# NANO112AN_v1 register map
File version: 1.0
Registers are 32-bit, read-write, reset 0x0 unless marked. A register's access mark holds for its fields unless they carry their own. Offsets are from the block's base; [hi:lo] are bit positions; {n}, {i} and the like mark numbered series; 'fields as' and 'values as' point back to an identical list.

## TMR0 — TMR Register Map
Base 0x40010000
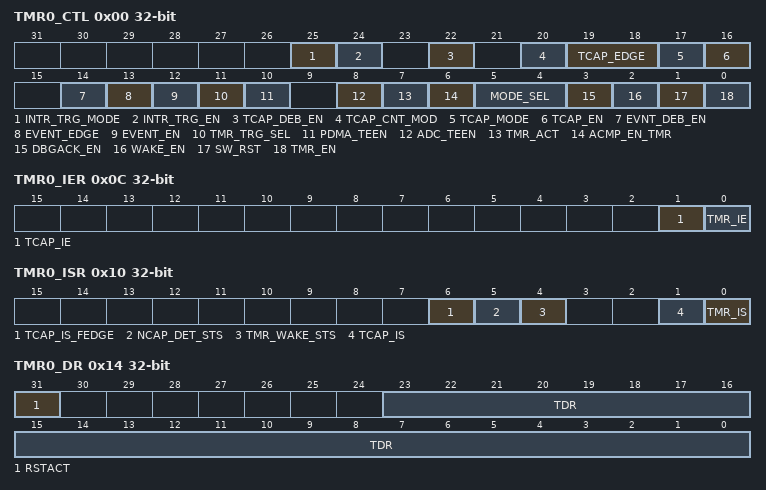
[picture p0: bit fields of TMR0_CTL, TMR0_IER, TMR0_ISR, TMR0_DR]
0x00 TMR0_CTL — Timer 0 Control Register
  [25] INTR_TRG_MODE — Inter-timer Trigger Mode Selection. This bit controls the timer operation mode when inter-timer trigger function is enabled. When this bit is low, the TMRx will be in counter mode and counting with external Clock Source or event. In addition, TMRx+1 will be in trigger-counting mode of capture function. In this mode, TMRx_CMPR control when inter-timer trigger function terminated. When this bit is high, the TMRx will be in counter mode and counting with external Clock Source or event. In addition, TMRx+1 will be in trigger-counting mode of capture function. In this mode, TMRx+1_CMPR control when inter-timer trigger function terminated. In this mode, TMRx would ignore some incoming event based on the EVNT_DROP_CNT (TMRx_ECTL[31:24]). And once the TMRx+1 counter value equal or large than TMRx+1_CMPR, TMRx would terminate the operation when next incoming event received. Note: For TMRx+1_CTL, this bit is ignored and the read back value is always 0.
    0=Inter-Timer Trigger function wouldn't ignore any incoming event; 1=Inter-Timer Trigger function would ignore incoming event based on the EVNT_DROP_CNT (TMRx_ECTL[31:24])
  [24] INTR_TRG_EN — Inter-timer Trigger Function Enable Control. This bit controls if Inter-timer Trigger function is enabled. If Inter-timer Trigger function is enabled, the TMRx will be in counter mode and counting with external Clock Source or event. In addition, TMRx+1 will be in trigger-counting mode of capture function. Note: For TMRx+1_CTL, this bit is ignored and the read back value is always 0.
    0=Inter-timer trigger function Disabled; 1=Inter-timer trigger function Enabled
  [22] TCAP_DEB_EN — TC Pin De-bounce Enable Control. When CAP_DEB_EN (TMRx_CTL[22]) is set, the TC pin de-bounce circuit will be enabled to eliminate the bouncing of the signal. In de-bounce circuit the TC pin signal will be sampled 4 times by TMRx_CLK. Note: When TCAP_EN (TMRx_CTL[16]) is enabled, enable this bit is recommended. And, while TCAP_EN (TMRx_CTL[16]) is disabled, disable this bit is recommended to save power consumption. Note: When CAP_SRC (TMRx_ECTL[16]) is high, the capture signal is from internal of chip and the de-bounce circuit would not take effect no matter this bit is high or low. Note: For Timer 1 and 3, when INTR_TRG_EN (TMRx_CTL[24]) is high, the capture signal is from internal of chip and the de-bounce circuit would not take effect no matter this bit is high or low.
    0=De-bounce circuit Disabled; 1=De-bounce circuit Enabled
  [20] TCAP_CNT_MOD — Timer Capture Counting Mode Selection. This bit indicates the behavior of 24-bit up-counting timer while TCAP_EN (TMRx_CTL[16]) is set to high. If this bit is 0, the free-counting mode, the behavior of 24-bit up-counting timer is defined by MODE_SEL (TMRx_CTL[5:4]) field. When TCAP_EN (TMRx_CTL[16]) is set, TCAP_MODE (TMRx_CTL[17]) is 0, and the transition of TC pin matches the TCAP_EDGE (TMRx_CTL[19:18]) setting, the value of 24-bit up-counting timer will be saved into register TMRx_TCAP. If this bit is 1, Trigger-counting mode, 24-bit up-counting timer will be not counting and keep its value at 0. When TCAP_EN (TMRx_CTL[16]) is set, TCAP_MODE (TMRx_CTL[17]) is 0, and once the transition of external pin matches the 1st transition of TCAP_EDGE (TMRx_CTL[19:18]) setting, the 24-bit up-counting timer will start counting. And then if the transition of external pin matches the 2nd transition of TCAP_EDGE (TMRx_CTL[19:18]) setting, the 24-bit up-counting timer will stop counting. And its value will be saved into register TMRx_TCAP.
    0=Capture with free-counting timer mode; 1=Capture with trigger-counting timer mode
  [19:18] TCAP_EDGE — TC Pin Edge Detect Selection
  [17] TCAP_MODE — TC Pin Function Mode Selection. This bit indicates if the transition on TC pin is used as timer counter reset function or timer capture function.
    0=The transition on TC pin is used as timer capture function; 1=The transition on TC pin is used as timer counter reset function
  [16] TCAP_EN — TC Pin Functional Enable Control. This bit controls if the transition on TC pin could be used as timer counter reset function or timer capture function.
    0=The transition on TC pin is ignored; 1=The transition on TC pin will result in the capture or reset of 24-bit timer counter
  [14] EVNT_DEB_EN — External Event De-bounce Enable Control. When EVNT_DEB_EN is set, the external event pin de-bounce circuit will be enabled to eliminate the bouncing of the signal. In de-bounce circuit the external event pin will be sampled 4 times by TMRx_CLK. Note: When EVENT_EN (TMRx_CTL[12]) is enabled, enable this bit is recommended. And, while EVENT_EN (TMRx_CTL[12]) is disabled, disable this bit is recommended to save power consumption.
    0=De-bounce circuit Disabled; 1=De-bounce circuit Enabled
  [13] EVENT_EDGE — Event Counting Mode Edge Selection. This bit indicates which edge of external event pin enabling the timer to increase 1.
    0=A falling edge of external event enabling the timer to increase 1; 1=A rising edge of external event enabling the timer to increase 1
  [12] EVENT_EN — Event Counting Mode Enable Control. When EVENT_EN is set, the increase of 24-bit up-counting timer is controlled by external event pin. While the transition of external event pin matches the definition of EVENT_EDGE (TMRx_CTL[13]), the 24-bit up-counting timer increases by 1. Or, the 24-bit up-counting timer will keep its value unchanged.
    0=Timer counting is not controlled by external event pin; 1=Timer counting is controlled by external event pin
  [11] TMR_TRG_SEL — Timer Trigger Selection. This bit controls if the TMR_IS (TMRx_ISR[0]) or TCAP_IS (TMRx_ISR[1]) is used to trigger PDMA and ADC while TMR_IS (TMRx_ISR[0]) or TCAP_IS (TMRx_ISR[1]) is set. If this bit is low and TMR_IS (TMRx_ISR[0]) is set, timer will generate an internal trigger event to PDMA or ADC while related trigger enable bit (PDMA_TEEN (TMRx_CTL[10]) or ADC_TEEN (TMRx_CTL[8])) is set. If this bit is set high and TCAP_IS (TMRx_ISR[0]) is set, timer will generate an internal trigger event to PDMA or ADC while related trigger enable bit (PDMA_TEEN (TMRx_CTL[10]) or ADC_TEEN (TMRx_CTL[8])) is set.
    0=TMR_IS (TMRx_ISR[0]) is used to trigger PDMA and ADC; 1=TCAP_IS (TMRx_ISR[1]) is used to trigger PDMA and ADC
  [10] PDMA_TEEN — Timer Trigger PDMA Enable Control. This bit controls if TMR_IS (TMRx_ISR[0]) or TCAP_IS (TMRx_ISR[1]) could trigger PDMA. When PDMA_TEEN is set, TMR_IS (TMRx_ISR[0]) is set and the CAP_TRG_EN (TMRx_CTL[11]) is low, the timer controller will generate an internal trigger event to PDMA controller. When PDMA_TEEN is set, TCAP_IS (TMRx_ISR[1]) is set and the CAP_TRG_EN (TMRx_CTL[11]) is high, the timer controller will generate an internal trigger event to PDMA controller.
    0=TMR_IS (TMRx_ISR[0]) or TCAP_IS (TMRx_ISR[1]) trigger PDMA Disabled; 1=TMR_IS (TMRx_ISR[0]) or TCAP_IS (TMRx_ISR[1]) trigger PDMA Enabled
  [8] ADC_TEEN — Timer Trigger ADC Enable Control. This bit controls if TMR_IS (TMRx_ISR[0]) or TCAP_IS (TMRx_ISR[1]) could trigger ADC. When ADC_TEEN is set, TMR_IS (TMRx_ISR[0]) is set and the CAP_TRG_EN (TMRx_CTL[11]) is low, the timer controller will generate an internal trigger event to ADC controller. When ADC_TEEN is set, TCAP_IS (TMRx_ISR[1]) is set and the CAP_TRG_EN (TMRx_CTL[11]) is high, the timer controller will generate an internal trigger event to ADC controller.
    0=TMR_IS (TMRx_ISR[0]) or TCAP_IS (TMRx_ISR[1]) trigger ADC Disabled; 1=TMR_IS (TMRx_ISR[0]) or TCAP_IS (TMRx_ISR[1]) trigger ADC Enabled
  [7] TMR_ACT ro — Timer Active Status Bit (Read Only). This bit indicates the timer counter status of timer.
    0=Timer is not active; 1=Timer is in active
  [6] ACMP_EN_TMR — ACMP Trigger Timer Enable Control. This bit high enables the functionality that when ACMP0 is in sigma-delta mode, it could enable Timer.
    0=ACMP0 trigger timer functionality disabled; 1=ACMP0 trigger timer functionality enabled
  [5:4] MODE_SEL — Timer Operating Mode Select
  [3] DBGACK_EN — ICE Debug Mode Acknowledge Ineffective Enable Control
    0=ICE debug mode acknowledgement effects TIMER counting and TIMER counter will be held while ICE debug mode acknowledged; 1=ICE debug mode acknowledgement is ineffective and TIMER counter will keep going no matter ICE debug mode acknowledged or not
  [2] WAKE_EN — Wake-up Enable Control. When WAKE_EN is set and the TMR_IS (TMRx_ISR[0]) or TCAP_IS (TMRx_ISR[1]) is set, the timer controller will generate a wake-up trigger event to CPU.
    0=Wake-up trigger event Disabled; 1=Wake-up trigger event Enabled
  [1] SW_RST — Software Reset. Set this bit will reset the timer counter, pre-scale counter and also force TMR_EN (TMRx_CTL [0]) to 0. Note: This bit will be auto cleared and takes at least 3 TMRx_CLK clock cycles.
    0=No effect; 1=Reset Timer's pre-scale counter, internal 24-bit up-counter and TMR_EN (TMRx_CTL [0]) bit
  [0] TMR_EN — Timer Counter Enable Control
    0=Stops/Suspends counting; 1=Starts counting
0x04 TMR0_PRECNT — Timer 0 Pre-scale Counter Register
  [7:0] PRESCALE_CNT — Pre-scale Counter
0x08 TMR0_CMPR — Timer 0 Compare Register
  [23:0] TMR_CMP — Timer Compared Value. TMR_CMP is a 24-bit compared register. When the internal 24-bit up-counter counts and its value is equal to TMR_CMP value, a Timer Interrupt is requested if the timer interrupt is enabled with TMR_EN (TMRx_CTL [0]) is enabled. The TMR_CMP value defines the timer counting cycle time. Note1: Never write 0x0 or 0x1 in TMR_CMP, or the core will run into unknown state. Note2: No matter TMR_EN (TMRx_CTL [0]) is 0 or 1, whenever software write a new value into this register, TIMER will restart counting using this new value and abort previous count.
0x0C TMR0_IER — Timer 0 Interrupt Enable Register
  [1] TCAP_IE — Timer Capture Function Interrupt Enable Control. Note: If timer external pin function interrupt is enabled, the timer asserts its interrupt signal when the TCAP_EN (TMRx_CTL[16]) is set and the transition of external pin matches the TCAP_EDGE (TMRx_CTL[19:18]) setting
    0=Timer External Pin Function Interrupt Disabled; 1=Timer External Pin Function Interrupt Enabled
  [0] TMR_IE — Timer Interrupt Enable Control. Note: If timer interrupt is enabled, the timer asserts its interrupt signal when the associated counter is equal to TMR_CMPR.
    0=Timer Interrupt Disabled; 1=Timer Interrupt Enabled
0x10 TMR0_ISR — Timer 0 Interrupt Status Register
  [6] TCAP_IS_FEDGE — TC Pin Edge Detect Is Falling. This flag indicates the edge detected in TC pin is rising edge or falling edge. Timer only updates this flag when it udpates the Timer Capture Data (TMR_TCAP[23:0]) value. When a new incoming capture event detected before CPU clearing the TCAP_IS (TMRx_ISR[1]) status, Timer will keep this bit unchanged.
    0=TC pin edge detected is rising edge; 1=TC pin edge detected is falling edge
  [5] NCAP_DET_STS — New Capture Detected Status. This status is to indicate there is a new incoming capture event detected before CPU clearing the TCAP_IS (TMRx_ISR[1]) status. If the above condition occurred, the Timer will keep register TMRx_TCAP unchanged and drop the new capture value. Write 1 to clear this bit to 0.
    0=New incoming capture event didn't detect before CPU clearing TCAP_IS (TMRx_ISR[1]) status; 1=New incoming capture event detected before CPU clearing TCAP_IS (TMRx_ISR[1]) status
  [4] TMR_WAKE_STS — Timer Wake-up Status. If timer causes CPU wakes up from Power-down mode, this bit will be set to high. It must be cleared by software with a write 1 to this bit.
    0=Timer does not cause system wake-up; 1=Wakes system up from Power-down mode by Timer timeout
  [1] TCAP_IS — Timer Capture Function Interrupt Status. This bit indicates the external pin function interrupt status of Timer. This bit is set by hardware when TCAP_EN (TMRx_CTL[16]) is set high, and the transition of external pin matches the TCAP_EDGE (TMRx_CTL[19:18]) setting. Write 1 to clear this bit to 0. If this bit is active and TCAP_IE (TMRx_IER[1]) is enabled, Timer will trigger an interrupt to CPU.
  [0] TMR_IS — Timer Interrupt Status. This bit indicates the interrupt status of Timer. This bit is set by hardware when the up counting value of internal 24-bit counter matches the timer compared value (TMR_CMPR). Write 1 to clear this bit to 0. If this bit is active and TMR_IE (TMRx_IER[0]) is enabled, Timer will trigger an interrupt to CPU.
0x14 TMR0_DR — Timer 0 Data Register
  [31] RSTACT — Reset Active. This bit indicates if the counter reset operation active. When user write this register, timer starts to reset its internal 24-bit timer up-counter and 8-bit pre-scale counter to 0. In the same time, timer set this flag to 1 to indicate the counter reset operation is in progress. Once the counter reset operation done, timer clear this bit to 0 automatically. Note: This bit is read only. Write operation wouldn't take any effect.
    0=Reset operation done; 1=Reset operation triggered by writing TMR_DR is in progress
  [23:0] TDR — Timer Data Register (Read). User can read this register for internal 24-bit timer up-counter value. Counter Reset (Write). User can write any value to this register to reset internal 24-bit timer up-counter and 8-bit pre-scale counter. This reset operation wouldn't affect any other timer control registers and circuit. After reset completed, the 24-bit timer up-counter and 8-bit pre-scale counter restart the counting based on the TMRx_CTL register setting.
0x18 TMR0_TCAP ro — Timer 0 Capture Data Register
  [23:0] CAP — Timer Capture Data Register. When TCAP_EN (TMRx_CTL[16]) is set, TCAP_MODE (TMRx_CTL[17]) is 0, TCAP_CNT_MOD (TMRx_CTL[20]) is 0, and the transition of external pin matches the TCAP_EDGE (TMRx_CTL[19:18]) setting, the value of 24-bit up-counting timer will be saved into register TMRx_TCAP. When TCAP_EN (TMRx_CTL[16]) is set, TCAP_MODE (TMRx_CTL[17]) is 0, TCAP_CNT_MOD (TMRx_CTL[20]) is 1, and the transition of external pin matches the 2nd transition of TCAP_EDGE (TMRx_CTL[19:18]) setting, the value of 24-bit up-counting timer will be saved into register TMRx_TCAP. User can read this register to get the counter value. When a new incoming capture event detected before CPU clearing the TCAP_IS (TMRxISR[1]) status, Timer will keep this filed value unchanged and drop the new capture value.
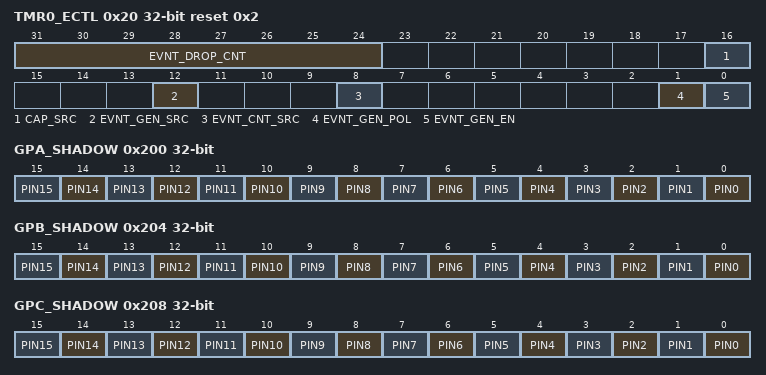
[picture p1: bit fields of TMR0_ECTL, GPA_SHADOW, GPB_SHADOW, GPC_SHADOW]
0x20 TMR0_ECTL reset 0x2 — Timer 0 Extended Control Register
  [31:24] EVNT_DROP_CNT — Event Drop Count. This field indicates timer to drop how many events after inter-timer trigger function enable. For example, if user writes 0x7 to this field, timer would drop 7 first incoming events and starts the inter-timer trigger operation when it get 8th event.
  [16] CAP_SRC — Capture Function Source Selection. This bit defines timer counter reset function or timer capture function controlled by transition of TC pin or transition of internal signals from other functional blocks of this chip. Note: When this bit is high, the EVNT_DEB_EN (TMRx_CTL[14]) would not take effect.
    0=Transition of TC pin selected; 1=Transition of internal signals from ACMP0
  [12] EVNT_GEN_SRC — Event Generator Reference Input Source Selection. This bit defines the event generator function controlled by external event pin or internal event signals from ACMP0.
    0=The event generator reference source is from external event pin; 1=The event generator reference source is from ACMP0
  [8] EVNT_CNT_SRC — Event Counting Source Selection
    0=The event counting source is from external event pin; 1=The event counting source is from TMRx's event generator output
  [1] EVNT_GEN_POL — Event Generator Reference Input Source Polarity Selection. When this bit is low and EVNT_GEN_EN (TMRx_ECTL[0]) is high, timer would generate a high pulse event out when it increases the 24-bit up counter and the polarity of signal defined by EVNT_GEN_SRC (TMRx_ECTL[12]) is low. When this bit is high and EVNT_GEN_EN (TMRx_ECTL[0]) is high, timer would generate a low pulse event pulse out when it increases the 24-bit up counter and the polarity of signal defined by EVNT_GEN_SRC (TMRx_ECTL[12]) is high. This bit only affects timer's operation when EVNT_GEN_EN (TMRx_ECTL[0]) is high.
    0=Timer generates a high pulse event out when it increase the 24-bit up counter and the polarity of signal defined by EVNT_GEN_SRC (TMRx_ECTL[12]) is low; 1=Timer generates a high pulse event out when it increase the 24-bit up counter and the polarity of signal defined by EVNT_GEN_SRC (TMRx_ECTL[12]) is high
  [0] EVNT_GEN_EN — Event Generator Function Enable Control. When this bit is high, timer would generate a high pulse event out when it increases the 24-bit up counter and the polarity of signal defined by EVNT_GEN_SRC (TMRx_ECTL[12]) is same as the polarity defined by EVNT_GEN_POL (TMRx_ECTL[1]).
    0=Event generator function disabled; 1=Event generator function enabled
0x200 GPA_SHADOW ro (reset mask 0xFFFF0000) — GPIO Port A Pin Value Shadow Register
  [n] PIN{n} (n=0..15) — GPIO Port [A/B/C/D/E/F] Pin Values. The value read from each of these bit reflects the actual status of the respective GPIO pin. These registers are shadow registers of GPIOx_PIN register. Note 1: For GPE_SHADOW, bits [15:10] are reserved. Note 1: For GPF_SHADOW, bits [15:6] are reserved.
0x204 GPB_SHADOW ro (reset mask 0xFFFF0000) — GPIO Port B Pin Value Shadow Register
  fields as GPA_SHADOW
0x208 GPC_SHADOW ro (reset mask 0xFFFF0000) — GPIO Port C Pin Value Shadow Register
  fields as GPA_SHADOW
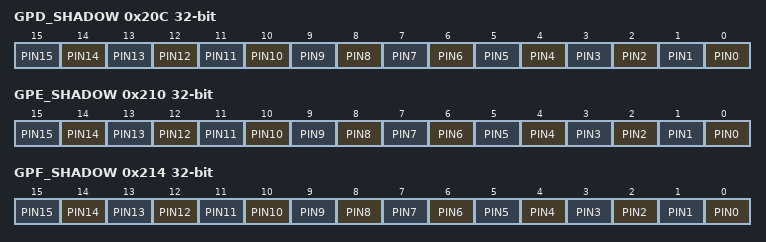
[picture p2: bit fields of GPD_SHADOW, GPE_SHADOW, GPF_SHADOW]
0x20C GPD_SHADOW ro (reset mask 0xFFFF0000) — GPIO Port D Pin Value Shadow Register
  fields as GPA_SHADOW
0x210 GPE_SHADOW ro (reset mask 0xFFFF0000) — GPIO Port E Pin Value Shadow Register
  fields as GPA_SHADOW
0x214 GPF_SHADOW ro (reset mask 0xFFFF0000) — GPIO Port F Pin Value Shadow Register
  fields as GPA_SHADOW
